# AT32F403xx register map
Vendor: Keil; Series: AT32F403; File version: 1.0
CPU: CM4 r0p1, little endian, no MPU, FPU, 4 interrupt priority bits
Registers are 32-bit, read-write, reset 0x0 unless marked. A register's access mark holds for its fields unless they carry their own. Offsets are from the block's base; [hi:lo] are bit positions; {n}, {i} and the like mark numbered series.

## TMR1 — Advanced timer
Base 0x40012C00
Same registers: TMR8 0x40013400, TMR15 0x40014000
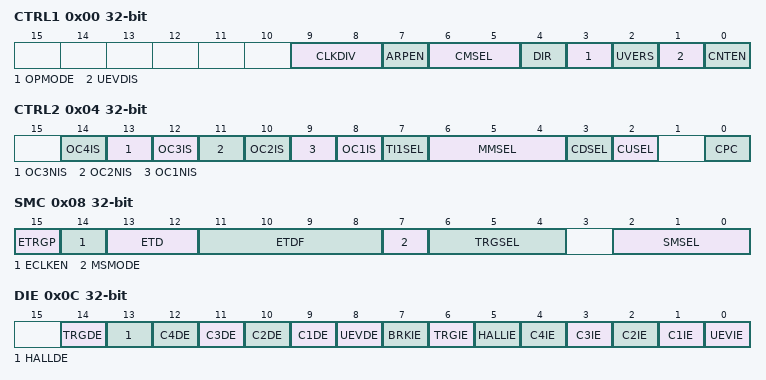
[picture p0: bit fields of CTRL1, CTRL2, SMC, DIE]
0x00 CTRL1 — control register 1
  [9:8] CLKDIV — Clock division
  [7] ARPEN — Auto-reload preload enable
  [6:5] CMSEL — Center-aligned mode selection
  [4] DIR — Direction
  [3] OPMODE — One-pulse mode
  [2] UVERS — Update request source
  [1] UEVDIS — Update disable
  [0] CNTEN — Counter enable
0x04 CTRL2 — control register 2
  [2n+6] OC{n}IS (n=1..4) — Output Idle state {n}
  [13] OC3NIS — Output Idle state 3
  [11] OC2NIS — Output Idle state 2
  [9] OC1NIS — Output Idle state 1
  [7] TI1SEL — TI1 selection
  [6:4] MMSEL — Master mode selection
  [3] CDSEL — Capture/compare DMA selection
  [2] CUSEL — Capture/compare control update selection
  [0] CPC — Capture/compare preloaded control
0x08 SMC — slave mode control register
  [15] ETRGP — External trigger polarity
  [14] ECLKEN — External clock enable
  [13:12] ETD — External trigger prescaler
  [11:8] ETDF — External trigger filter
  [7] MSMODE — Master/Slave mode
  [6:4] TRGSEL — Trigger selection
  [2:0] SMSEL — Slave mode selection
0x0C DIE — DMA/Interrupt enable register
  [14] TRGDE — Trigger DMA request enable
  [13] HALLDE — HALL DMA request enable
  [n+8] C{n}DE (n=1..4) — Capture/Compare {n} DMA request enable
  [8] UEVDE — Update DMA request enable
  [7] BRKIE — Break interrupt enable
  [6] TRGIE — Trigger interrupt enable
  [5] HALLIE — HALL interrupt enable
  [n] C{n}IE (n=1..4) — Capture/Compare {n} interrupt enable
  [0] UEVIE — Update interrupt enable
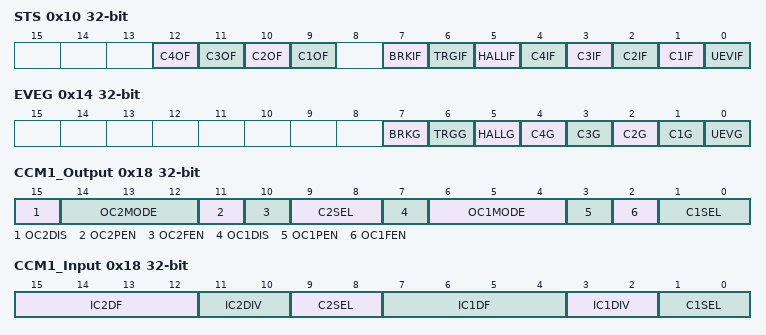
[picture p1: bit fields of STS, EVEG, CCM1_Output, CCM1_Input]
0x10 STS — status register
  [12] C4OF — Capture/Compare 4 overcapture flag
  [11] C3OF — Capture/Compare 3 overcapture flag
  [10] C2OF — Capture/compare 2 overcapture flag
  [9] C1OF — Capture/Compare 1 overcapture flag
  [7] BRKIF — Break interrupt flag
  [6] TRGIF — Trigger interrupt flag
  [5] HALLIF — HALL interrupt flag
  [4] C4IF — Capture/Compare 4 interrupt flag
  [3] C3IF — Capture/Compare 3 interrupt flag
  [2] C2IF — Capture/Compare 2 interrupt flag
  [1] C1IF — Capture/compare 1 interrupt flag
  [0] UEVIF — Update interrupt flag
0x14 EVEG — event generation register
  [7] BRKG — Break generation
  [6] TRGG — Trigger generation
  [5] HALLG — Capture/Compare control update generation
  [n] C{n}G (n=1..4) — Capture/compare {n} generation
  [0] UEVG — Update generation
0x18 CCM1_Output — capture/compare mode register (output mode)
  [15] OC2DIS — Output Compare 2 clear enable
  [14:12] OC2MODE — Output Compare 2 mode
  [11] OC2PEN — Output Compare 2 preload enable
  [10] OC2FEN — Output Compare 2 fast enable
  [9:8] C2SEL — Capture/Compare 2 selection
  [7] OC1DIS — Output Compare 1 clear enable
  [6:4] OC1MODE — Output Compare 1 mode
  [3] OC1PEN — Output Compare 1 preload enable
  [2] OC1FEN — Output Compare 1 fast enable
  [1:0] C1SEL — Capture/Compare 1 selection
0x18 CCM1_Input (alternate view of CCM1_Output) — capture/compare mode register 1 (input mode)
  [15:12] IC2DF — Input capture 2 filter
  [11:10] IC2DIV — Input capture 2 prescaler
  [9:8] C2SEL — Capture/Compare 2 selection
  [7:4] IC1DF — Input capture 1 filter
  [3:2] IC1DIV — Input capture 1 prescaler
  [1:0] C1SEL — Capture/Compare 1 selection
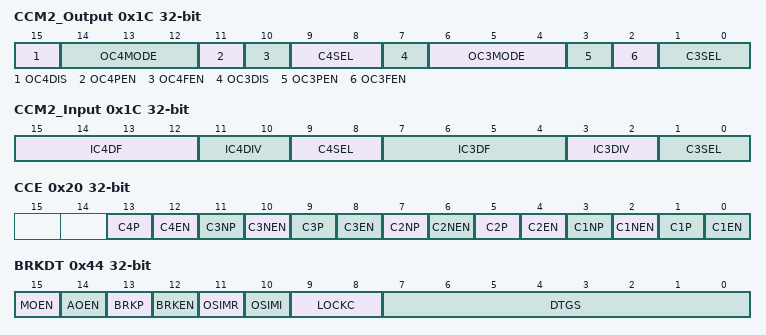
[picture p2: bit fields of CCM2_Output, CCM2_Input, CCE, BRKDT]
0x1C CCM2_Output — capture/compare mode register (output mode)
  [15] OC4DIS — Output compare 4 clear enable
  [14:12] OC4MODE — Output compare 4 mode
  [11] OC4PEN — Output compare 4 preload enable
  [10] OC4FEN — Output compare 4 fast enable
  [9:8] C4SEL — Capture/Compare 4 selection
  [7] OC3DIS — Output compare 3 clear enable
  [6:4] OC3MODE — Output compare 3 mode
  [3] OC3PEN — Output compare 3 preload enable
  [2] OC3FEN — Output compare 3 fast enable
  [1:0] C3SEL — Capture/Compare 3 selection
0x1C CCM2_Input (alternate view of CCM2_Output) — capture/compare mode register 2 (input mode)
  [15:12] IC4DF — Input capture 4 filter
  [11:10] IC4DIV — Input capture 4 prescaler
  [9:8] C4SEL — Capture/Compare 4 selection
  [7:4] IC3DF — Input capture 3 filter
  [3:2] IC3DIV — Input capture 3 prescaler
  [1:0] C3SEL — Capture/compare 3 selection
0x20 CCE — capture/compare enable register
  [13] C4P — Capture/Compare 3 output Polarity
  [4n-4] C{n}EN (n=1..4) — Capture/Compare {n} output enable
  [11] C3NP — Capture/Compare 3 output Polarity
  [10] C3NEN — Capture/Compare 3 complementary output enable
  [9] C3P — Capture/Compare 3 output Polarity
  [7] C2NP — Capture/Compare 2 output Polarity
  [6] C2NEN — Capture/Compare 2 complementary output enable
  [5] C2P — Capture/Compare 2 output Polarity
  [3] C1NP — Capture/Compare 1 output Polarity
  [2] C1NEN — Capture/Compare 1 complementary output enable
  [1] C1P — Capture/Compare 1 output Polarity
0x24 CNT — counter
  [15:0] CNT — counter value
0x28 DIV — prescaler
  [15:0] DIV — Prescaler value
0x2C AR — auto-reload register
  [15:0] AR — Auto-reload value
0x30 RC — repetition counter register
  [7:0] RC — Repetition counter value
0x34 CC1 — capture/compare register 1
  [15:0] CC1 — Capture/Compare 1 value
0x38 CC2 — capture/compare register 2
  [15:0] CC2 — Capture/Compare 2 value
0x3C CC3 — capture/compare register 3
  [15:0] CC3 — Capture/Compare value
0x40 CC4 — capture/compare register 4
  [15:0] CC4 — Capture/Compare value
0x44 BRKDT — break and dead-time register
  [15] MOEN — Main output enable
  [14] AOEN — Automatic output enable
  [13] BRKP — Break polarity
  [12] BRKEN — Break enable
  [11] OSIMR — Off-state selection for Run mode
  [10] OSIMI — Off-state selection for Idle mode
  [9:8] LOCKC — Lock configuration
  [7:0] DTGS — Dead-time generator setup
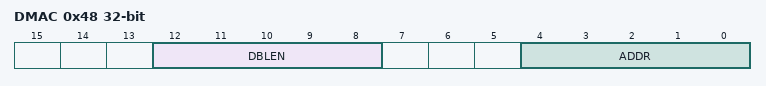
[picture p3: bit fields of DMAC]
0x48 DMAC — DMA control register
  [12:8] DBLEN — DMA burst length
  [4:0] ADDR — DMA base address
0x4C DMABA — DMA address for full transfer
  [15:0] DMABA — DMA register for burst accesses

## Notices in the file
Copyright (C) 2012-2014 ARM Limited. All rights reserved.
Purpose: System Viewer Description (SVD) Example (Schema Version 1.1)
This is a description of a none-existent and incomplete device
for demonstration purposes only.
Redistribution and use in source and binary forms, with or without
modification, are permitted provided that the following conditions are met:
- Redistributions of source code must retain the above copyright
notice, this list of conditions and the following disclaimer.
- Redistributions in binary form must reproduce the above copyright
notice, this list of conditions and the following disclaimer in the
documentation and/or other materials provided with the distribution.
- Neither the name of ARM nor the names of its contributors may be used
to endorse or promote products derived from this software without
specific prior written permission.
THIS SOFTWARE IS PROVIDED BY THE COPYRIGHT HOLDERS AND CONTRIBUTORS "AS IS"
AND ANY EXPRESS OR IMPLIED WARRANTIES, INCLUDING, BUT NOT LIMITED TO, THE
IMPLIED WARRANTIES OF MERCHANTABILITY AND FITNESS FOR A PARTICULAR PURPOSE
ARE DISCLAIMED. IN NO EVENT SHALL COPYRIGHT HOLDERS AND CONTRIBUTORS BE
LIABLE FOR ANY DIRECT, INDIRECT, INCIDENTAL, SPECIAL, EXEMPLARY, OR
CONSEQUENTIAL DAMAGES (INCLUDING, BUT NOT LIMITED TO, PROCUREMENT OF
SUBSTITUTE GOODS OR SERVICES; LOSS OF USE, DATA, OR PROFITS; OR BUSINESS
INTERRUPTION) HOWEVER CAUSED AND ON ANY THEORY OF LIABILITY, WHETHER IN
CONTRACT, STRICT LIABILITY, OR TORT (INCLUDING NEGLIGENCE OR OTHERWISE)
ARISING IN ANY WAY OUT OF THE USE OF THIS SOFTWARE, EVEN IF ADVISED OF THE
POSSIBILITY OF SUCH DAMAGE.
